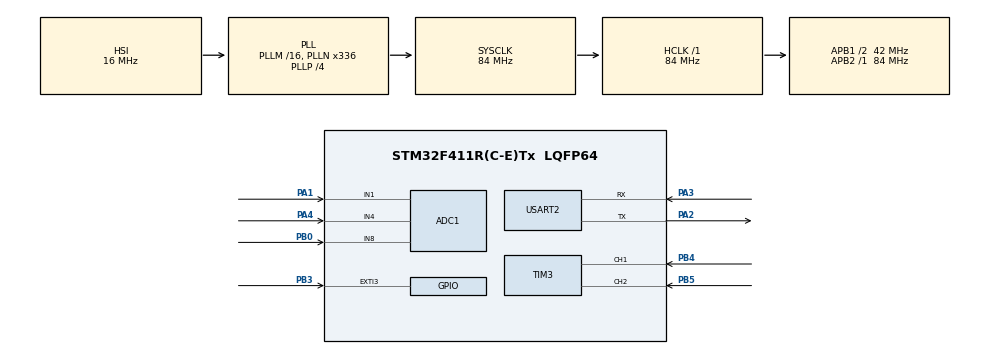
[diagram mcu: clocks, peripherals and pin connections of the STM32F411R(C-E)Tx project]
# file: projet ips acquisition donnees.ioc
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ADC1.Channel-1\#ChannelRegularConversion=ADC_CHANNEL_1
ADC1.ContinuousConvMode=ENABLE
ADC1.DMAContinuousRequests=ENABLE
ADC1.NbrOfConversionFlag=1
ADC1.Rank-1\#ChannelRegularConversion=1
ADC1.SamplingTime-1\#ChannelRegularConversion=ADC_SAMPLETIME_3CYCLES
ADC1.ScanConvMode=ENABLE
ADC1.master=1
Dma.ADC1.0.Direction=DMA_PERIPH_TO_MEMORY
Dma.ADC1.0.FIFOMode=DMA_FIFOMODE_DISABLE
Dma.ADC1.0.Instance=DMA2_Stream0
Dma.ADC1.0.MemDataAlignment=DMA_MDATAALIGN_HALFWORD
Dma.ADC1.0.MemInc=DMA_MINC_ENABLE
Dma.ADC1.0.Mode=DMA_CIRCULAR
Dma.ADC1.0.PeriphDataAlignment=DMA_PDATAALIGN_HALFWORD
Dma.ADC1.0.PeriphInc=DMA_PINC_DISABLE
Dma.ADC1.0.Priority=DMA_PRIORITY_LOW
Dma.Request0=ADC1
Mcu.Family=STM32F4
Mcu.Name=STM32F411R(C-E)Tx
Mcu.Package=LQFP64
NVIC.ADC_IRQn=true\:0\:0\:false\:false\:true\:true\:true\:true
NVIC.DMA2_Stream0_IRQn=true\:0\:0\:false\:false\:true\:false\:true\:true
NVIC.PriorityGroup=NVIC_PRIORITYGROUP_0
PA1.Signal=ADCx_IN1
PA2.Mode=Asynchronous
PA2.Signal=USART2_TX
PA3.Mode=Asynchronous
PA3.Signal=USART2_RX
PA4.Signal=ADCx_IN4
PB0.Signal=ADCx_IN8
PB3.Signal=GPXTI3
PB4.Signal=S_TIM3_CH1
PB5.Signal=S_TIM3_CH2
ProjectManager.HeapSize=0x200
ProjectManager.StackSize=0x400
ProjectManager.TargetToolchain=STM32CubeIDE
RCC.48MHZClocksFreq_Value=84000000
RCC.AHBFreq_Value=84000000
RCC.APB1CLKDivider=RCC_HCLK_DIV2
RCC.APB1Freq_Value=42000000
RCC.APB1TimFreq_Value=84000000
RCC.APB2Freq_Value=84000000
RCC.APB2TimFreq_Value=84000000
RCC.CortexFreq_Value=84000000
RCC.FLatency-AdvancedSettings=FLASH_LATENCY_2
RCC.HCLKFreq_Value=84000000
RCC.HSE_VALUE=8000000
RCC.HSI_VALUE=16000000
RCC.LSE_VALUE=32768
RCC.PLLN=336
RCC.PLLP=RCC_PLLP_DIV4
RCC.SYSCLKFreq_VALUE=84000000
RCC.SYSCLKSource=RCC_SYSCLKSOURCE_PLLCLK
RCC.VCOOutputFreq_Value=336000000
SH.ADCx_IN1.0=ADC1_IN1,IN1
SH.ADCx_IN4.0=ADC1_IN4,IN4
SH.ADCx_IN8.0=ADC1_IN8,IN8
SH.S_TIM3_CH1.0=TIM3_CH1,Encoder_Interface
SH.S_TIM3_CH2.0=TIM3_CH2,Encoder_Interface
TIM3.AutoReloadPreload=TIM_AUTORELOAD_PRELOAD_ENABLE
USART2.VirtualMode=VM_ASYNC
board=NUCLEO-F411RE

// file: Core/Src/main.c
/* USER CODE BEGIN Header */
/**
  ******************************************************************************
  * @file           : main.c
  * @brief          : Main program body
  ******************************************************************************
  * @attention
  *
  * Copyright (c) 2025 STMicroelectronics.
  * All rights reserved.
  *
  * This software is licensed under terms that can be found in the LICENSE file
  * in the root directory of this software component.
  * If no LICENSE file comes with this software, it is provided AS-IS.
  *
  ******************************************************************************
  */
/* USER CODE END Header */
#include "main.h"

/* USER CODE BEGIN Includes */
#define VREF 3.3f             // Tension de référence de l’ADC
#define ADC_RESOLUTION 4096.0f
#define SENSITIVITY   0.300f  // V/g typique pour ADXL335
#define NB_CALIB_SAMPLES 100
/* USER CODE END Includes */

/* USER CODE BEGIN PTD */
// Convertit une valeur brute ADC en tension (V)
float adc_to_voltage(uint32_t adc_value) {
    return (adc_value * VREF) / ADC_RESOLUTION;
}

// Convertit une tension en accélération (g)
float voltage_to_g(float voltage, float zeroG_voltage) {
    return (voltage - zeroG_voltage) / SENSITIVITY;
}
/* USER CODE END PTD */

/* USER CODE BEGIN PD */

#define SENSITIVITY   0.300f  // V/G, typique pour ADXL335
#define NB_CALIB_SAMPLES 100
#define value_potar 100
/* USER CODE END PD */

ADC_HandleTypeDef hadc1;
DMA_HandleTypeDef hdma_adc1;

TIM_HandleTypeDef htim3;

UART_HandleTypeDef huart2;

/* USER CODE BEGIN PV */
uint32_t adcValues[3];         // Valeurs ADC X, Y, Z
float zeroG_X = 0, zeroG_Y = 0, zeroG_Z = 0;  // Référence 0g
char msg[100];                 // Buffer pour UART
/* USER CODE END PV */

void SystemClock_Config(void);
static void MX_GPIO_Init(void);
static void MX_DMA_Init(void);
static void MX_ADC1_Init(void);
static void MX_TIM3_Init(void);
static void MX_USART2_UART_Init(void);

int main(void)
{
	  HAL_Init();
	  SystemClock_Config();

	  MX_GPIO_Init();
	  MX_DMA_Init();
	  MX_ADC1_Init();
	  MX_TIM3_Init();
	  MX_USART2_UART_Init();
	  HAL_TIM_Encoder_Start(&htim3, TIM_CHANNEL_ALL);

	  // === CALIBRATION INITIALE ===
	  for (int i = 0; i < NB_CALIB_SAMPLES; i++) {
	      for (int axis = 0; axis < 3; axis++) {
	          HAL_ADC_Start(&hadc1);
	          HAL_ADC_PollForConversion(&hadc1, HAL_MAX_DELAY);
	          adcValues[axis] = HAL_ADC_GetValue(&hadc1);
	          HAL_ADC_Stop(&hadc1);
	      }

	      zeroG_X += adc_to_voltage(adcValues[0]);
	      zeroG_Y += adc_to_voltage(adcValues[1]);
	      zeroG_Z += adc_to_voltage(adcValues[2]);
	      HAL_Delay(10);
	  }

	  zeroG_X /= NB_CALIB_SAMPLES;
	  zeroG_Y /= NB_CALIB_SAMPLES;
	  zeroG_Z /= NB_CALIB_SAMPLES;

	  sprintf(msg, "Calibration done.\r\n");
	  HAL_UART_Transmit(&huart2, (uint8_t*)msg, strlen(msg), HAL_MAX_DELAY);

	  // === BOUCLE PRINCIPALE ===
	  while (1) {
	      for (int i = 0; i < 3; i++) {
	          HAL_ADC_Start(&hadc1);
	          HAL_ADC_PollForConversion(&hadc1, HAL_MAX_DELAY);
	          adcValues[i] = HAL_ADC_GetValue(&hadc1);
	          HAL_ADC_Stop(&hadc1);

	      float voltageX = adc_to_voltage(adcValues[0]);
	      float voltageY = adc_to_voltage(adcValues[1]);
	      float voltageZ = adc_to_voltage(adcValues[2]);

	      int32_t  accelX = (int32_t)(voltage_to_g(voltageX, zeroG_X));
	      int32_t  accelY = (int32_t)(voltage_to_g(voltageY, zeroG_Y));
	      int32_t  accelZ = (int32_t)(voltage_to_g(voltageZ, zeroG_Z));

	      sprintf(msg, "Accel [g] -> X: %ld, Y: %ld, Z: %ld\r\n", accelX, accelY, accelZ);
	      HAL_UART_Transmit(&huart2, (uint8_t*)msg, strlen(msg), HAL_MAX_DELAY);

	      HAL_Delay(500);
	  }
	}

  // Fréquence d’échantillonnage

    /* USER CODE END WHILE */

void SystemClock_Config(void)
{
  RCC_OscInitTypeDef RCC_OscInitStruct = {0};
  RCC_ClkInitTypeDef RCC_ClkInitStruct = {0};

  /** Configure the main internal regulator output voltage
  */
  __HAL_RCC_PWR_CLK_ENABLE();
  __HAL_PWR_VOLTAGESCALING_CONFIG(PWR_REGULATOR_VOLTAGE_SCALE1);

  /** Initializes the RCC Oscillators according to the specified parameters
  * in the RCC_OscInitTypeDef structure.
  */
  RCC_OscInitStruct.OscillatorType = RCC_OSCILLATORTYPE_HSI;
  RCC_OscInitStruct.HSIState = RCC_HSI_ON;
  RCC_OscInitStruct.HSICalibrationValue = RCC_HSICALIBRATION_DEFAULT;
  RCC_OscInitStruct.PLL.PLLState = RCC_PLL_ON;
  RCC_OscInitStruct.PLL.PLLSource = RCC_PLLSOURCE_HSI;
  RCC_OscInitStruct.PLL.PLLM = 16;
  RCC_OscInitStruct.PLL.PLLN = 336;
  RCC_OscInitStruct.PLL.PLLP = RCC_PLLP_DIV4;
  RCC_OscInitStruct.PLL.PLLQ = 4;
  if (HAL_RCC_OscConfig(&RCC_OscInitStruct) != HAL_OK)
  {
    Error_Handler();
  }

  /** Initializes the CPU, AHB and APB buses clocks
  */
  RCC_ClkInitStruct.ClockType = RCC_CLOCKTYPE_HCLK|RCC_CLOCKTYPE_SYSCLK
                              |RCC_CLOCKTYPE_PCLK1|RCC_CLOCKTYPE_PCLK2;
  RCC_ClkInitStruct.SYSCLKSource = RCC_SYSCLKSOURCE_PLLCLK;
  RCC_ClkInitStruct.AHBCLKDivider = RCC_SYSCLK_DIV1;
  RCC_ClkInitStruct.APB1CLKDivider = RCC_HCLK_DIV2;
  RCC_ClkInitStruct.APB2CLKDivider = RCC_HCLK_DIV1;

  if (HAL_RCC_ClockConfig(&RCC_ClkInitStruct, FLASH_LATENCY_2) != HAL_OK)
  {
    Error_Handler();
  }
}

static void MX_ADC1_Init(void)
{

  ADC_ChannelConfTypeDef sConfig = {0};

  /** Configure the global features of the ADC (Clock, Resolution, Data Alignment and number of conversion)
  */
  hadc1.Instance = ADC1;
  hadc1.Init.ClockPrescaler = ADC_CLOCK_SYNC_PCLK_DIV4;
  hadc1.Init.Resolution = ADC_RESOLUTION_12B;
  hadc1.Init.ScanConvMode = ENABLE;
  hadc1.Init.ContinuousConvMode = ENABLE;
  hadc1.Init.DiscontinuousConvMode = DISABLE;
  hadc1.Init.ExternalTrigConvEdge = ADC_EXTERNALTRIGCONVEDGE_NONE;
  hadc1.Init.ExternalTrigConv = ADC_SOFTWARE_START;
  hadc1.Init.DataAlign = ADC_DATAALIGN_RIGHT;
  hadc1.Init.NbrOfConversion = 3;
  hadc1.Init.DMAContinuousRequests = ENABLE;
  hadc1.Init.EOCSelection = ADC_EOC_SINGLE_CONV;
  if (HAL_ADC_Init(&hadc1) != HAL_OK)
  {
    Error_Handler();
  }

  /** Configure for the selected ADC regular channel its corresponding rank in the sequencer and its sample time.
  */
  sConfig.Channel = ADC_CHANNEL_1;
  sConfig.Rank = 1;
  sConfig.SamplingTime = ADC_SAMPLETIME_3CYCLES;
  if (HAL_ADC_ConfigChannel(&hadc1, &sConfig) != HAL_OK)
  {
    Error_Handler();
  }
  sConfig.Channel = ADC_CHANNEL_4;
  sConfig.Rank = 2;
  sConfig.SamplingTime = ADC_SAMPLETIME_3CYCLES;
  if (HAL_ADC_ConfigChannel(&hadc1, &sConfig) != HAL_OK)
  {
    Error_Handler();
  }
  sConfig.Channel = ADC_CHANNEL_8;
  sConfig.Rank = 3;
  sConfig.SamplingTime = ADC_SAMPLETIME_3CYCLES;
  if (HAL_ADC_ConfigChannel(&hadc1, &sConfig) != HAL_OK)
  {
    Error_Handler();
  }
  /* USER CODE END ADC1_Init 2 */

}

static void MX_TIM3_Init(void)
{

  TIM_Encoder_InitTypeDef sConfig = {0};
  TIM_MasterConfigTypeDef sMasterConfig = {0};

  htim3.Instance = TIM3;
  htim3.Init.Prescaler = 0;
  htim3.Init.CounterMode = TIM_COUNTERMODE_UP;
  htim3.Init.Period = 65535;
  htim3.Init.ClockDivision = TIM_CLOCKDIVISION_DIV1;
  htim3.Init.AutoReloadPreload = TIM_AUTORELOAD_PRELOAD_ENABLE;
  sConfig.EncoderMode = TIM_ENCODERMODE_TI1;
  sConfig.IC1Polarity = TIM_ICPOLARITY_RISING;
  sConfig.IC1Selection = TIM_ICSELECTION_DIRECTTI;
  sConfig.IC1Prescaler = TIM_ICPSC_DIV1;
  sConfig.IC1Filter = 0;
  sConfig.IC2Polarity = TIM_ICPOLARITY_RISING;
  sConfig.IC2Selection = TIM_ICSELECTION_DIRECTTI;
  sConfig.IC2Prescaler = TIM_ICPSC_DIV1;
  sConfig.IC2Filter = 0;
  if (HAL_TIM_Encoder_Init(&htim3, &sConfig) != HAL_OK)
  {
    Error_Handler();
  }
  sMasterConfig.MasterOutputTrigger = TIM_TRGO_RESET;
  sMasterConfig.MasterSlaveMode = TIM_MASTERSLAVEMODE_DISABLE;
  if (HAL_TIMEx_MasterConfigSynchronization(&htim3, &sMasterConfig) != HAL_OK)
  {
    Error_Handler();
  }

}

static void MX_USART2_UART_Init(void)
{

  huart2.Instance = USART2;
  huart2.Init.BaudRate = 115200;
  huart2.Init.WordLength = UART_WORDLENGTH_8B;
  huart2.Init.StopBits = UART_STOPBITS_1;
  huart2.Init.Parity = UART_PARITY_NONE;
  huart2.Init.Mode = UART_MODE_TX_RX;
  huart2.Init.HwFlowCtl = UART_HWCONTROL_NONE;
  huart2.Init.OverSampling = UART_OVERSAMPLING_16;
  if (HAL_UART_Init(&huart2) != HAL_OK)
  {
    Error_Handler();
  }

}

static void MX_DMA_Init(void)
{

  /* DMA controller clock enable */
  __HAL_RCC_DMA2_CLK_ENABLE();

  /* DMA interrupt init */
  /* DMA2_Stream0_IRQn interrupt configuration */
  HAL_NVIC_SetPriority(DMA2_Stream0_IRQn, 0, 0);
  HAL_NVIC_EnableIRQ(DMA2_Stream0_IRQn);

}

static void MX_GPIO_Init(void)
{
  GPIO_InitTypeDef GPIO_InitStruct = {0};

  /* GPIO Ports Clock Enable */
  __HAL_RCC_GPIOA_CLK_ENABLE();
  __HAL_RCC_GPIOB_CLK_ENABLE();

  /*Configure GPIO pin : PB3 */
  GPIO_InitStruct.Pin = GPIO_PIN_3;
  GPIO_InitStruct.Mode = GPIO_MODE_IT_RISING;
  GPIO_InitStruct.Pull = GPIO_NOPULL;
  HAL_GPIO_Init(GPIOB, &GPIO_InitStruct);

}

void Error_Handler(void)
{
  __disable_irq();
  while (1)
  {
  }
}
